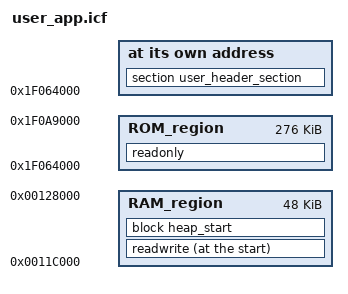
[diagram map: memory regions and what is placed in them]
/*###ICF### Section handled by ICF editor, don't touch! ****/
/*-Editor annotation file-*/
/* IcfEditorFile="$TOOLKIT_DIR$\config\ide\IcfEditor\cortex_v1_0.xml" */
/*-Specials-*/

/*-Memory Regions-*/
define symbol __ICFEDIT_region_ROM_start__ = 0x1f064000;
define symbol __ICFEDIT_region_ROM_end__   = 0x1f0A9000;
define symbol __ICFEDIT_region_RAM_start__ = 0x0011C000;
define symbol __ICFEDIT_region_RAM_end__   = 0x00128000;
/*-Sizes-*/

/**** End of ICF editor section. ###ICF###*/

define memory mem with size = 4G;
define region ROM_region   = mem:[from __ICFEDIT_region_ROM_start__   to __ICFEDIT_region_ROM_end__];
define region RAM_region   = mem:[from __ICFEDIT_region_RAM_start__   to __ICFEDIT_region_RAM_end__];

define block heap_start with fixed order{ section .ram_data_end};

initialize by copy { readwrite };
do not initialize  { section .noinit };

place at address mem:__ICFEDIT_region_ROM_start__ { section user_header_section };

place in ROM_region   { readonly };
place at start of RAM_region  {readwrite};
place in RAM_region  { block heap_start};

define exported symbol _ram_end_ = __ICFEDIT_region_RAM_end__;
